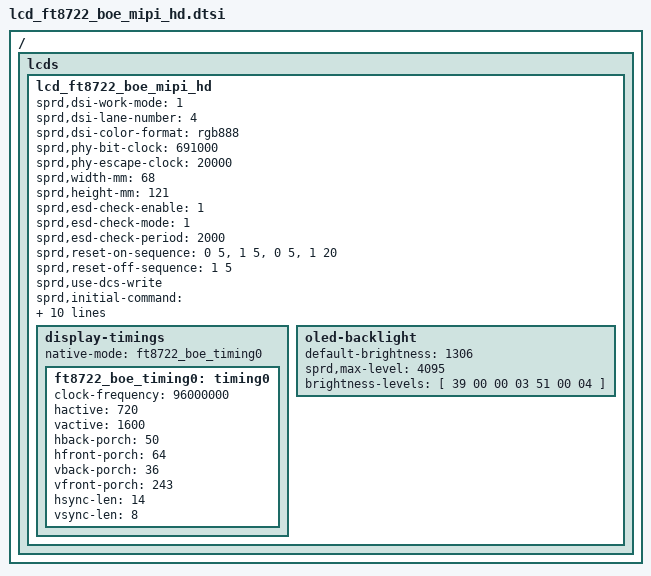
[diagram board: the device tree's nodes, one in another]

/*
 * R61350 Truly LCD config dtsi file for spreadtrum
 *
 * Copyright (C) 2018, Spreadtrum Communications Inc.
 *
 * SPDX-License-Identifier: (GPL-2.0+ OR MIT)
 */

/ {
	fragment {
		target-path = "/";
		__overlay__ {
			lcds {
				lcd_ft8722_boe_mipi_hd: lcd_ft8722_boe_mipi_hd {

					sprd,dsi-work-mode = <1>; /* video burst mode*/
					sprd,dsi-lane-number = <4>;
					sprd,dsi-color-format = "rgb888";

					sprd,phy-bit-clock = <691000>;	/* kbps */
					sprd,phy-escape-clock = <20000>;/* kHz */

					sprd,width-mm = <68>;
					sprd,height-mm = <121>;

					sprd,esd-check-enable = <1>;
					sprd,esd-check-mode = <1>;
					sprd,esd-check-period = <2000>;
					/* sprd,esd-check-register = <0x0A>; */
					/* sprd,esd-check-value = <0x9C>; */

					sprd,reset-on-sequence = <0 5>, <1 5>, <0 5>, <1 20>;
					sprd,reset-off-sequence = <1 5>;

 
					sprd,use-dcs-write;
					sprd,initial-command = [
						39 00 00 02 00 00 
						39 00 00 04 FF 87 22 01 
						39 00 00 02 00 80 
						39 00 00 03 FF 87 22 
						39 00 00 02 00 A1 
						39 00 00 07 B3 02 D0 06 40 20 98 
						39 00 00 02 00 82 
						39 00 00 02 B4 06 
						39 00 00 02 1C 02 
						39 00 00 02 00 A1 
						39 00 00 02 C1 CC 
						39 00 00 02 00 F6 
						39 00 00 02 CF 3C 
						39 00 00 02 00 F1 
						39 00 00 02 CF 3C 
						39 00 00 02 00 F7 
						39 00 00 02 CF 11 
						39 00 00 02 00 71 
						39 00 00 06 C0 C8 00 F2 00 2C 
						39 00 00 02 00 A6 
						39 00 00 02 C1 02 
						39 00 00 02 00 E0 
						39 00 00 02 CE 00 
						39 00 00 02 00 80 
						39 00 00 02 CE 00 
						39 00 00 02 00 D0 
						39 00 00 09 CE 01 00 0A 01 01 00 E3 01 
						39 00 00 02 00 E8 
						39 00 00 05 CE 00 E3 00 E3 
						39 00 00 02 00 70 
						39 00 00 05 CF 06 06 3F 43 
						39 00 00 02 00 C5 
						39 00 00 05 CF 06 06 41 45 
						39 00 00 02 00 80 
						39 00 00 03 C1 33 33 
						39 00 00 02 00 90 
						39 00 00 02 C1 02 
						39 00 00 02 00 F5 
						39 00 00 02 CF 02 
						39 00 00 02 00 80 
						39 00 00 0D C2 83 01 00 82 82 01 00 82 8C 01 00 82 
						39 00 00 02 00 90 
						39 00 00 05 C2 00 00 00 00 
						39 00 00 02 00 A0 
						39 00 00 10 C2 8A 07 00 00 89 89 08 00 00 89 88 09 00 00 89 
						39 00 00 02 00 B0 
						39 00 00 06 C2 87 0A 00 00 89 
						39 00 00 02 00 E0 
						39 00 00 05 C2 33 33 00 00 
						39 00 00 02 00 D0 
						39 00 00 11 C3 35 30 00 30 35 30 00 30 35 30 00 30 00 00 00 00 
						39 00 00 02 00 E0 
						39 00 00 0A C3 35 00 00 00 35 00 00 00 35 
						39 00 00 02 00 80 
						39 00 00 11 CB 00 CD CD 00 CD 00 00 CD 02 CE CD 00 CF 00 00 CC 
						39 00 00 02 00 90 
						39 00 00 11 CB 00 00 0C 00 0C 00 00 00 00 0C 00 00 00 00 00 00 
						39 00 00 02 00 A0 
						39 00 00 09 CB 00 00 00 00 0C C0 30 00 
						39 00 00 02 00 B0 
						39 00 00 05 CB 14 41 A4 C0 
						39 00 00 02 00 C0 
						39 00 00 05 CB 14 41 A4 C0 
						39 00 00 02 00 D5 
						39 00 00 0C CB 83 00 83 83 00 83 83 00 83 83 00 
						39 00 00 02 00 E0 
						39 00 00 0E CB 83 83 00 83 83 00 83 83 00 83 83 00 83 
						39 00 00 02 00 80 
						39 00 00 11 CC 00 00 00 00 00 00 00 25 25 00 24 29 29 18 17 16 
						39 00 00 02 00 90 
						39 00 00 09 CC 07 09 04 26 26 22 24 03 
						39 00 00 02 00 A0 
						39 00 00 11 CC 00 00 00 00 00 00 00 25 25 00 24 29 29 18 17 16 
						39 00 00 02 00 B0 
						39 00 00 09 CC 08 06 04 26 26 24 22 02 
						39 00 00 02 00 80 
						39 00 00 11 CD 00 00 00 00 00 00 00 25 25 00 24 29 29 18 17 16 
						39 00 00 02 00 90 
						39 00 00 09 CD 06 08 04 26 26 22 24 02 
						39 00 00 02 00 A0 
						39 00 00 11 CD 00 00 00 00 00 00 00 25 25 00 24 29 29 18 17 16 
						39 00 00 02 00 B0 
						39 00 00 09 CD 09 07 04 26 26 24 22 03 
						39 00 00 02 00 86 
						39 00 00 09 C0 01 00 01 01 3A 3A 3A 04 
						39 00 00 02 00 96 
						39 00 00 09 C0 01 00 01 01 3A 3A 3A 04 
						39 00 00 02 00 A6 
						39 00 00 09 C0 01 00 01 01 3A 3A 3A 04 
						39 00 00 02 00 A3 
						39 00 00 07 CE 01 00 01 01 3A 04 
						39 00 00 02 00 B3 
						39 00 00 07 CE 01 00 01 01 3A 04 
						39 00 00 02 00 76 
						39 00 00 09 C0 01 00 01 01 3A 3A 3A 04 
						39 00 00 02 00 82 
						39 00 00 02 A7 00 
						39 00 00 02 00 93 
						39 00 00 02 C5 32 
						39 00 00 02 00 97 
						39 00 00 02 C5 32 
						39 00 00 02 00 9A 
						39 00 00 02 C5 32 
						39 00 00 02 00 9C 
						39 00 00 02 C5 32 
						39 00 00 02 00 B6 
						39 00 00 09 C5 0F 0F 0F 0F 1C 1C 00 00 
						39 00 00 02 00 00 
						39 00 00 03 D8 2B 2B 
						39 00 00 02 00 8F 
						39 00 00 02 C5 20 
						39 00 00 02 00 88 
						39 00 00 02 C4 08 
						39 00 00 02 00 80 
						39 00 00 02 A7 11 
						39 00 00 02 00 A0 
						39 00 00 11 C3 35 01 23 45 21 03 45 00 00 00 21 03 45 01 23 45 
						39 00 00 02 00 B1 
						39 00 00 02 F5 1F 
						39 00 00 02 00 CB 
						39 00 00 02 C0 51 
						39 00 00 02 00 94 
						39 00 00 02 E9 00 
						39 00 00 02 00 9A 
						39 00 00 02 C4 11 
						39 00 00 02 00 95 
						39 00 00 02 E9 10 
						39 00 00 02 00 80 
						39 00 00 02 C5 77 
						39 00 00 02 00 E8 
						39 00 00 02 C0 40 
						39 00 00 02 00 B1 
						39 00 00 02 C5 4A 
						39 00 00 02 00 B4 
						39 00 00 02 C5 4A 
						39 00 00 02 00 B2 
						39 00 00 02 C5 39 
						39 00 00 02 00 B5 
						39 00 00 02 C5 0E 
						39 00 00 02 00 9C 
						39 00 00 02 F5 00 
						39 00 00 02 00 9E 
						39 00 00 02 F5 00 
						39 00 00 02 00 B0 
						39 00 00 02 C5 D0 
						39 00 00 02 00 B3 
						39 00 00 02 C5 D0 
						39 00 00 02 00 99 
						39 00 00 02 CF 50 
						39 00 00 02 00 00 
						39 00 00 29 E1 00 03 07 0F 15 1A 22 28 33 0E 3C 43 49 4E 07 53 5C 63 6A 8B 72 79 80 89 1E 93 98 9F A6 70 AE B8 C5 CC 50 D5 E0 E7 EB 0E 
						39 00 00 02 00 30 
						39 00 00 29 E1 00 03 07 0F 15 1A 22 28 33 0E 3C 43 49 4E 07 53 5C 63 6A 8B 72 79 80 89 1E 93 98 9F A6 70 AE B8 C5 CC 50 D5 E0 E7 EB 0E 
						39 00 00 02 00 60 
						39 00 00 29 E1 00 02 07 0F 3D 1A 22 29 33 13 3C 43 49 4E 07 53 5C 63 6A 8B 72 79 80 89 0C 93 98 9E A5 1A AD B7 C4 CB F0 D4 DF E6 EA 4A 
						39 00 00 02 00 90 
						39 00 00 29 E1 00 02 07 0F 3D 1A 22 29 33 13 3C 43 49 4E 07 53 5C 63 6A 8B 72 79 80 89 0C 93 98 9E A5 1A AD B7 C4 CB F0 D4 DF E6 EA 4A 
						39 00 00 02 00 C0 
						39 00 00 29 E1 00 03 06 0E 0F 19 21 28 32 52 3B 42 49 4E B2 53 5B 63 6A BB 72 79 80 89 1E 93 99 9F A7 98 AF BA C8 D1 E6 DE ED F8 FF 78 
						39 00 00 02 00 F0 
						39 00 00 11 E1 00 03 06 0E 0F 19 21 28 32 52 3B 42 49 4E B2 53 
						39 00 00 02 00 00 
						39 00 00 19 E2 5B 63 6A BB 72 79 80 89 1E 93 99 9F A7 98 AF BA C8 D1 E6 DE ED F8 FF 78 
						39 00 00 02 00 E0 
						39 00 00 02 CF 34 
						39 00 00 02 00 85 
						39 00 00 02 A7 00 
						39 00 00 02 00 80 
						39 00 00 02 B3 22 
						39 00 00 02 00 B0 
						39 00 00 02 B3 00 
						39 00 00 02 00 83 
						39 00 00 02 B0 63 
						39 00 00 02 00 A1 
						39 00 00 02 B0 02 
						39 00 00 02 00 A0
						39 00 00 0D D6 9B 91 B4 C0 BF BA B6 B4 B2 B4 BB BF
						39 00 00 02 00 B0
						39 00 00 0D D6 7D 81 83 82 80 80 80 80 7E 7D 7E 7E
						39 00 00 02 00 C0
						39 00 00 0D D6 A0 8A B7 B7 B6 B2 AB A8 A5 A9 AD B1
						39 00 00 02 00 D0
						39 00 00 0D D6 7D 80 82 80 80 80 81 80 7F 7F 7E 80
						39 00 00 02 00 E0
						39 00 00 0D D6 9C 96 8D 92 9A 9B 86 88 8A 98 A0 9D
						39 00 00 02 00 F0
						39 00 00 0D D6 7F 81 81 7F 7D 80 81 7F 7E 7D 7F 81
						39 00 00 02 00 00
						39 00 00 0D D7 80 80 7F 80 80 80 76 74 76 80 80 80
						39 00 00 02 00 10
						39 00 00 0D D7 7F 82 81 7E 80 82 80 7D 7D 80 80 7F
						39 00 00 02 91 80
						39 00 00 02 00 B0
						39 00 00 04 CA 00 02 0C 
						39 00 00 02 00 00 
						39 00 00 04 FF FF FF FF 
						39 00 00 02 35 00
						05 78 00 01 11
						39 00 00 03 51 00 00
						39 00 00 02 53 24 
						39 0A 00 02 55 00 
						05 14 00 01 29
						];

                                       

					sprd,sleep-in-command = [
						05 14 00 01 28
						05 8C 00 01 10
						39 00 00 02 00 00
						39 00 00 05 F7 5A A5 95 27
						];

					sprd,sleep-out-command = [
						15 78 00 01 11
						15 14 00 01 29
						];

					sprd,cabc-off-command = [
						23 00 00 02 55 00
						];
					sprd,cabc-ui-command = [
						23 00 00 02 55 01
						];
					sprd,cabc-still-image-command = [
						23 00 00 02 55 02
						];
					sprd,cabc-video-command = [
						23 00 00 02 55 03
						];

					display-timings {
						native-mode = <&ft8722_boe_timing0>;

						ft8722_boe_timing0: timing0 {
							clock-frequency = <96000000>;
							hactive = <720>;
							vactive = <1600>;
							hback-porch = <50>;
							hfront-porch = <64>;
							vback-porch = <36>;
							vfront-porch = <243>;
							hsync-len = <14>;
							vsync-len = <8>;
						};
					};

					
					oled-backlight {			
						default-brightness = <1306>;	
						sprd,max-level = <4095>;
						brightness-levels = [				
							39 00 00 03 51 00 04	
						];
					};
				};
			};
		};
	};
};
